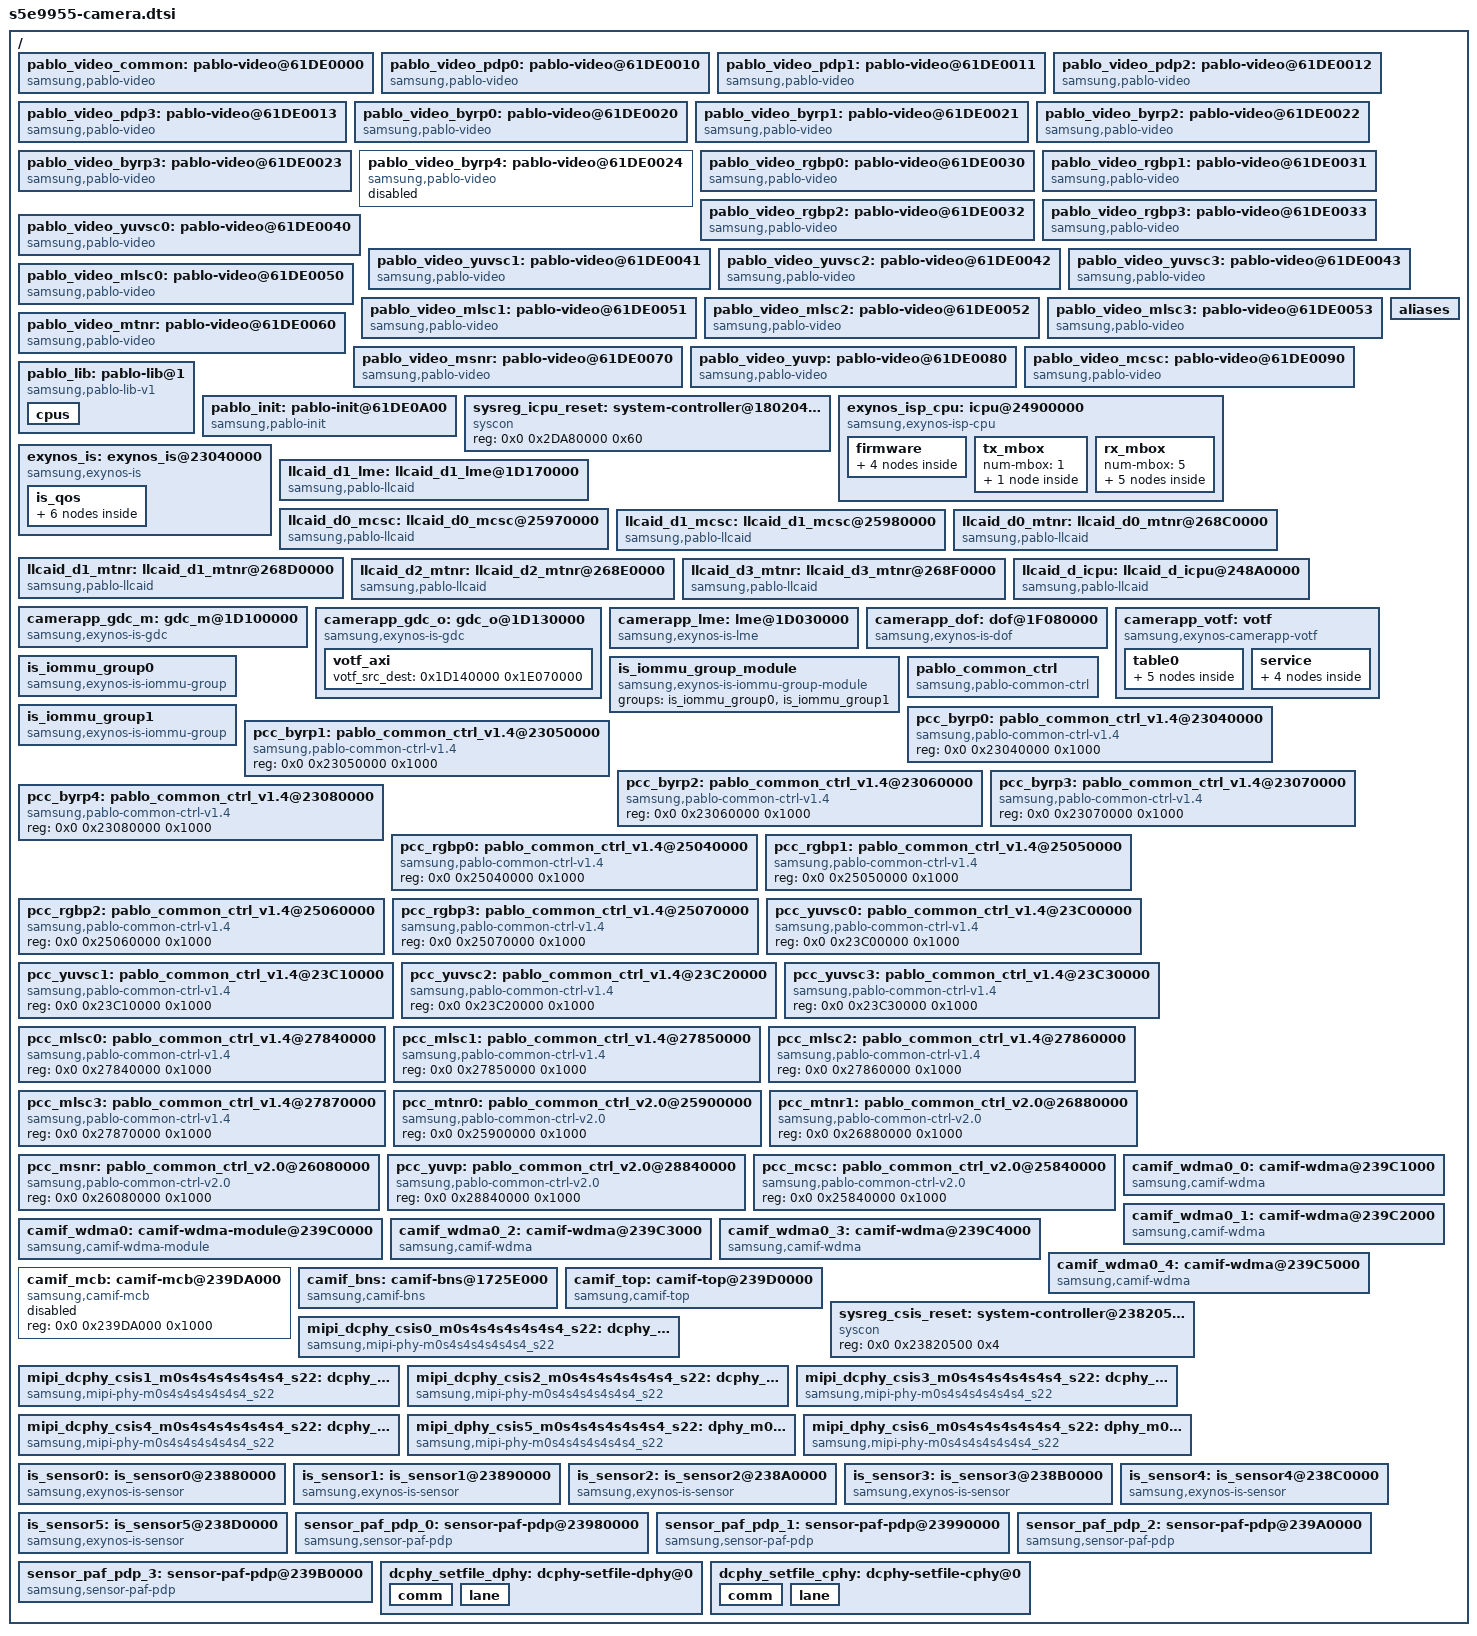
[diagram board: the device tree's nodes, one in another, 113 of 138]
// SPDX-License-Identifier: GPL-2.0
/*
 * SAMSUNG EXYNOS9955 SoC camera device tree source
 *
 * Copyright (c) 2024 Samsung Electronics Co., Ltd.
 *		http://www.samsung.com
 *
 * SAMSUNG EXYNOS9955 SoC camera device nodes are listed in this file.
 * EXYNOS9945 based board files can include this file and provide
 * values for board specific bindings.
 *
 * This program is free software; you can redistribute it and/or modify
 * it under the terms of the GNU General Public License version 2 as
 * published by the Free Software Foundation.
 */

#include <dt-bindings/clock/s5e9955.h>
#include <dt-bindings/interrupt-controller/arm-gic.h>
#include <dt-bindings/interrupt-controller/s5e9955.h>
#include <dt-bindings/camera/exynos_is_dt.h>
#include <dt-bindings/camera/votf.h>
#include "s5e9955-pinctrl.dtsi"

/ {
	pablo_video_common: pablo-video@61DE0000 {
		compatible = "samsung,pablo-video";
		device-type = <1>;	/* ISCHAIN */
		video-type = <0>;	/* LEADER */
		video-name = "COMMON";
		video-number = <0>;
		group-id = <36>;
		group-slot = <0>;

		pablo,v4l2-dev = <&exynos_is>;
	};

	pablo_video_pdp0: pablo-video@61DE0010 {
		compatible = "samsung,pablo-video";
		device-type = <1>;	/* ISCHAIN */
		video-type = <0>;	/* LEADER */
		video-name = "PDP0";
		video-number = <10>;
		group-id = <7>;
		group-slot = <1>;

		pablo,v4l2-dev = <&exynos_is>;
	};

	pablo_video_pdp1: pablo-video@61DE0011 {
		compatible = "samsung,pablo-video";
		device-type = <1>;	/* ISCHAIN */
		video-type = <0>;	/* LEADER */
		video-name = "PDP1";
		video-number = <11>;
		group-id = <8>;
		group-slot = <1>;

		pablo,v4l2-dev = <&exynos_is>;
	};

	pablo_video_pdp2: pablo-video@61DE0012 {
		compatible = "samsung,pablo-video";
		device-type = <1>;	/* ISCHAIN */
		video-type = <0>;	/* LEADER */
		video-name = "PDP2";
		video-number = <12>;
		group-id = <9>;
		group-slot = <1>;

		pablo,v4l2-dev = <&exynos_is>;
	};

	pablo_video_pdp3: pablo-video@61DE0013 {
		compatible = "samsung,pablo-video";
		device-type = <1>;	/* ISCHAIN */
		video-type = <0>;	/* LEADER */
		video-name = "PDP3";
		video-number = <13>;
		group-id = <10>;
		group-slot = <1>;

		pablo,v4l2-dev = <&exynos_is>;
	};

	pablo_video_byrp0: pablo-video@61DE0020 {
		compatible = "samsung,pablo-video";
		device-type = <1>;	/* ISCHAIN */
		video-type = <0>;	/* LEADER */
		video-name = "BYRP0";
		video-number = <20>;
		group-id = <15>;
		group-slot = <2>;

		pablo,v4l2-dev = <&exynos_is>;
	};

	pablo_video_byrp1: pablo-video@61DE0021 {
		compatible = "samsung,pablo-video";
		device-type = <1>;	/* ISCHAIN */
		video-type = <0>;	/* LEADER */
		video-name = "BYRP1";
		video-number = <21>;
		group-id = <16>;
		group-slot = <2>;

		pablo,v4l2-dev = <&exynos_is>;
	};

	pablo_video_byrp2: pablo-video@61DE0022 {
		compatible = "samsung,pablo-video";
		device-type = <1>;	/* ISCHAIN */
		video-type = <0>;	/* LEADER */
		video-name = "BYRP2";
		video-number = <22>;
		group-id = <17>;
		group-slot = <2>;

		pablo,v4l2-dev = <&exynos_is>;
	};

	pablo_video_byrp3: pablo-video@61DE0023 {
		compatible = "samsung,pablo-video";
		device-type = <1>;	/* ISCHAIN */
		video-type = <0>;	/* LEADER */
		video-name = "BYRP3";
		video-number = <23>;
		group-id = <18>;
		group-slot = <2>;

		pablo,v4l2-dev = <&exynos_is>;
	};

	pablo_video_byrp4: pablo-video@61DE0024 {
		compatible = "samsung,pablo-video";
		device-type = <1>;	/* ISCHAIN */
		video-type = <0>;	/* LEADER */
		video-name = "BYRP4";
		video-number = <24>;
		group-id = <19>;
		group-slot = <2>;

		pablo,v4l2-dev = <&exynos_is>;

		status = "disabled";
	};

	pablo_video_rgbp0: pablo-video@61DE0030 {
		compatible = "samsung,pablo-video";
		device-type = <1>;	/* ISCHAIN */
		video-type = <0>;	/* LEADER */
		video-name = "RGBP0";
		video-number = <30>;
		group-id = <20>;
		group-slot = <3>;

		pablo,v4l2-dev = <&exynos_is>;
	};

	pablo_video_rgbp1: pablo-video@61DE0031 {
		compatible = "samsung,pablo-video";
		device-type = <1>;	/* ISCHAIN */
		video-type = <0>;	/* LEADER */
		video-name = "RGBP1";
		video-number = <31>;
		group-id = <21>;
		group-slot = <3>;

		pablo,v4l2-dev = <&exynos_is>;
	};

	pablo_video_rgbp2: pablo-video@61DE0032 {
		compatible = "samsung,pablo-video";
		device-type = <1>;	/* ISCHAIN */
		video-type = <0>;	/* LEADER */
		video-name = "RGBP2";
		video-number = <32>;
		group-id = <22>;
		group-slot = <3>;

		pablo,v4l2-dev = <&exynos_is>;
	};

	pablo_video_rgbp3: pablo-video@61DE0033 {
		compatible = "samsung,pablo-video";
		device-type = <1>;	/* ISCHAIN */
		video-type = <0>;	/* LEADER */
		video-name = "RGBP3";
		video-number = <33>;
		group-id = <23>;
		group-slot = <3>;

		pablo,v4l2-dev = <&exynos_is>;
	};

	pablo_video_yuvsc0: pablo-video@61DE0040 {
		compatible = "samsung,pablo-video";
		device-type = <1>;	/* ISCHAIN */
		video-type = <0>;	/* LEADER */
		video-name = "YUVSC0";
		video-number = <40>;
		group-id = <24>;
		group-slot = <4>;

		pablo,v4l2-dev = <&exynos_is>;
	};

	pablo_video_yuvsc1: pablo-video@61DE0041 {
		compatible = "samsung,pablo-video";
		device-type = <1>;	/* ISCHAIN */
		video-type = <0>;	/* LEADER */
		video-name = "YUVSC1";
		video-number = <41>;
		group-id = <25>;
		group-slot = <4>;

		pablo,v4l2-dev = <&exynos_is>;
	};

	pablo_video_yuvsc2: pablo-video@61DE0042 {
		compatible = "samsung,pablo-video";
		device-type = <1>;	/* ISCHAIN */
		video-type = <0>;	/* LEADER */
		video-name = "YUVSC2";
		video-number = <42>;
		group-id = <26>;
		group-slot = <4>;

		pablo,v4l2-dev = <&exynos_is>;
	};

	pablo_video_yuvsc3: pablo-video@61DE0043 {
		compatible = "samsung,pablo-video";
		device-type = <1>;	/* ISCHAIN */
		video-type = <0>;	/* LEADER */
		video-name = "YUVSC3";
		video-number = <43>;
		group-id = <27>;
		group-slot = <4>;

		pablo,v4l2-dev = <&exynos_is>;
	};

	pablo_video_mlsc0: pablo-video@61DE0050 {
		compatible = "samsung,pablo-video";
		device-type = <1>;	/* ISCHAIN */
		video-type = <0>;	/* LEADER */
		video-name = "MLSC0";
		video-number = <50>;
		group-id = <28>;
		group-slot = <5>;

		pablo,v4l2-dev = <&exynos_is>;
	};

	pablo_video_mlsc1: pablo-video@61DE0051 {
		compatible = "samsung,pablo-video";
		device-type = <1>;	/* ISCHAIN */
		video-type = <0>;	/* LEADER */
		video-name = "MLSC1";
		video-number = <51>;
		group-id = <29>;
		group-slot = <5>;

		pablo,v4l2-dev = <&exynos_is>;
	};

	pablo_video_mlsc2: pablo-video@61DE0052 {
		compatible = "samsung,pablo-video";
		device-type = <1>;	/* ISCHAIN */
		video-type = <0>;	/* LEADER */
		video-name = "MLSC2";
		video-number = <52>;
		group-id = <30>;
		group-slot = <5>;

		pablo,v4l2-dev = <&exynos_is>;
	};

	pablo_video_mlsc3: pablo-video@61DE0053 {
		compatible = "samsung,pablo-video";
		device-type = <1>;	/* ISCHAIN */
		video-type = <0>;	/* LEADER */
		video-name = "MLSC3";
		video-number = <53>;
		group-id = <31>;
		group-slot = <5>;

		pablo,v4l2-dev = <&exynos_is>;
	};

	pablo_video_mtnr: pablo-video@61DE0060 {
		compatible = "samsung,pablo-video";
		device-type = <1>;	/* ISCHAIN */
		video-type = <0>;	/* LEADER */
		video-name = "MTNR";
		video-number = <60>;
		group-id = <32>;
		group-slot = <6>;

		pablo,v4l2-dev = <&exynos_is>;
	};

	pablo_video_msnr: pablo-video@61DE0070 {
		compatible = "samsung,pablo-video";
		device-type = <1>;	/* ISCHAIN */
		video-type = <0>;	/* LEADER */
		video-name = "MSNR";
		video-number = <70>;
		group-id = <33>;
		group-slot = <7>;

		pablo,v4l2-dev = <&exynos_is>;
	};

	pablo_video_yuvp: pablo-video@61DE0080 {
		compatible = "samsung,pablo-video";
		device-type = <1>;	/* ISCHAIN */
		video-type = <0>;	/* LEADER */
		video-name = "YUVP";
		video-number = <80>;
		group-id = <34>;
		group-slot = <8>;

		pablo,v4l2-dev = <&exynos_is>;
	};

	pablo_video_mcsc: pablo-video@61DE0090 {
		compatible = "samsung,pablo-video";
		device-type = <1>;	/* ISCHAIN */
		video-type = <0>;	/* LEADER */
		video-name = "MCSC";
		video-number = <90>;
		group-id = <35>;
		group-slot = <9>;

		pablo,v4l2-dev = <&exynos_is>;
		pablo,iommu-group = <&is_iommu_group0>;
	};

	pablo_lib: pablo-lib@1 {
		compatible = "samsung,pablo-lib-v1";
		status = "okay";

		cpus { /* 4:3:2:1 */
			cluster0 = <0>;		/* LIT */
			cluster1 = <4>;		/* MID_LF */
			cluster1h = <7>;	/* MID_HF */
			cluster2 = <9>;		/* BIG */
		};
	};

        pablo_init: pablo-init@61DE0A00 {
		compatible = "samsung,pablo-init";
		status = "okay";
	};

	sysreg_icpu_reset: system-controller@1802040c {
		compatible = "syscon";
		reg = <0x0 0x2DA80000 0x60>;
	};

	exynos_isp_cpu: icpu@24900000 {
		compatible = "samsung,exynos-isp-cpu";
		reg = <0x0 0x24900000 0x50>,
			<0x0 0x24910000 0x1000>,
			<0x0 0x24970000 0x2000>,
			<0x0 0x24980000 0x100>;
		reg-names = "mcuctl_core", "mcuctl", "sysctrl", "cstore";
		interrupts = <0 INTREQ__FROM_ICPU_TO_HOST_3 IRQ_TYPE_LEVEL_HIGH>, /* mbox0 */
				<0 INTREQ__FROM_ICPU_TO_HOST_4 IRQ_TYPE_LEVEL_HIGH>, /* mbox1 */
				<0 INTREQ__FROM_ICPU_TO_HOST_5 IRQ_TYPE_LEVEL_HIGH>, /* mbox2 */
				<0 INTREQ__FROM_ICPU_TO_HOST_6 IRQ_TYPE_LEVEL_HIGH>, /* mbox3 */
				<0 INTREQ__FROM_ICPU_TO_HOST_7 IRQ_TYPE_LEVEL_HIGH>; /* mbox4 */
		status = "okay";
		iommus = <&sysmmu_icpu_s0>;
		samsung,iommu-group = <&iommu_group_icpu>;
		samsung,reset-sysreg = <&sysreg_icpu_reset>;
		reset = <0 1>; /* reset bit, <core0 core1> */
		dma-coherent;
		samsung,iommu-reserved-map =
			<0x0 0x10000000 0x1000000>, /* FW binary */
			<0x0 0x00000000 0x10000000>, /* ICPU MMU */
			<0x0 0x24800000 0x200000>; /* ICPU SFR for using ICPU MMU 2M page*/
		memory-region = <&icpu_fw_rmem>;

		force-powerdown-seq =
			/* type addr mask val timeout */
			<0 0x24970024 0xFFFFFFFF 0x1      0>, /* Enable CA32 Transaction block */
			<0 0x24980030 0xFFFFFFFF 0x3      0>, /* DMA Flush */
			<1 0x24970028 0xFFFFFFFF 0x0   1000>, /* Wait until # of CA32  transaction is 0 */
			<1 0x24980034 0x24       0x24  1000>, /* Wait DMA  flush is done */

			<0 0x2497001C 0xFFFFFFFF 0x0      0>, /* Q-channel dependency disable */

			<0 0x24970004 0xFFFFFFFF 0x3F     0>, /* Q-channel disable(Always-on) */
			<0 0x24970030 0xFFFFFFFF 0x0      0>, /* Reset : Timers, WDT, GIC400, SYSCTRL */
			<0 0x2497002C 0xFFFFFFFF 0x0      0>, /* Reset : CA53, C_STORE */

			<0 0x2DA80040 0xFFFFFFFF 0x0     0>, /* PMU core reset : ICPU_CPU_OUT */
			<0 0x2DA8002C 0xFFFFFFFF 0x0     0>, /* PMU core reset : ICPU_CPU_OPTION */

			<0 0x24970004 0xFFFFFFFF 0x0     0>, /* Q-channel enable */
			<0 0x24970030 0xFFFFFFFF 0x3F    0>, /* Timers, WDT, GIC400, SYSCTRL */
			<0 0x2497002C 0xFFFFFFFF 0x3     0>, /* Core SW reset release */

			<0 0x24970050 0xFFFFFFFF 0x1     0>; /* Forced Power Down Enable */

		sw-reset-seq =
			<0 0x2DA80040 0xFFFFFFFF 0x0     0>, // ICPU_CPU_OUT in PMU_ICPU (PMU_SUB)
			<0 0x2DA8002C 0xFFFFFFFF 0x0     0>, // ICPU_CPU_OPTION in PMU_ICPU (PMU_SUB)

			// SW Reset Trigger for Peripherals
			<0 0x24970030 0xFFFFFFFF 0x0     0>, // Timers, WDT, GIC400, SYSCTRL
			<0 0x24970034 0xFFFFFFFF 0x0     0>, // MCUCTL_CORE/PERI

			<2 0x0        0xFFFFFFFF 0x0     1>, // delay 1us

			// SW Reset Release for Peripherals
			<0 0x24970030 0xFFFFFFFF 0x3F    0>, // Timers, WDT, GIC400, SYSCTRL
			<0 0x24970034 0xFFFFFFFF 0x3     0>, // MCUCTL_CORE/PERI

			<0 0x24970024 0xFFFFFFFF 0x0     0>, // Disable CA53 Transaction block
			<0 0x24970050 0xFFFFFFFF 0x0     0>, // Forced Power Down Disable
			<0 0x2497001C 0xFFFFFFFF 0x7     0>; // Q-channel dependency enable

		dbg-reg =
			/* start num */
			<0x0080 16>,
			<0x1490 40>;
		dbg-reg-name = "dbg", "mbox_dbg";

		num-cores = <2>; /* Dual core */

		samsung,imgloader-s2mpu-support;
		aarch64;
		firmware{
			binary{
				mem-id = <0>;
				cma-alloc;
				size = <0x1000000>;
				align = <0x200000>; /* 64K for S2MPU & ICPU MMU 2M page */
				signature-size = <0x210>; /* dec. 528 byte */
				signature-check;
				no-optimization;
			};

			heap{
				mem-id = <1>;
				dma-heap;
				heap-name = "system-uncached";
				size = <0x3700000>;
			};

			log{
				mem-id = <2>;
				dma-heap;
				heap-name = "system-uncached";
				size = <0x110000>;
			};

			/* mem-id = <3> is reserved for secure heap */

			dbg{
				mem-id = <4>;
				dma-heap;
				heap-name = "system-uncached";
				size = <0x100000>;
			};
		};

		tx_mbox{
			num-mbox = <1>;
			tx_mbox_0{
				int-enable-offset = <0x1004>;
				int-gen-offset = <0x1400>;
				int-status-offset = <0x100c>;
				max-data-len = <16>;
				data-offset = <0x1440>;
			};
		};

		rx_mbox{
			num-mbox = <5>;
			rx_mbox_0{
				int-gen-offset = <0x1200>;
				int-status-offset = <0x1008>;
				max-data-len = <8>;
				data-offset = <0x1240>;
			};
			rx_mbox_1{
				int-gen-offset = <0x1204>;
				int-status-offset = <0x1008>;
				max-data-len = <8>;
				data-offset = <0x1260>;
			};
			rx_mbox_2{
				int-gen-offset = <0x1208>;
				int-status-offset = <0x1008>;
				max-data-len = <8>;
				data-offset = <0x1280>;
			};
			rx_mbox_3{
				int-gen-offset = <0x120c>;
				int-status-offset = <0x1008>;
				max-data-len = <8>;
				data-offset = <0x12a0>;
			};
			rx_mbox_4{
				int-gen-offset = <0x1210>;
				int-status-offset = <0x1008>;
				max-data-len = <8>;
				data-offset = <0x12c0>;
			};
		};
	};

	exynos_is: exynos_is@23040000 {
		compatible = "samsung,exynos-is";
		reg = <0x0 0x23040000 0x6000>, /* BYRP0 */
			<0x0 0x23050000 0x6000>, /* BYRP1 */
			<0x0 0x23060000 0x6000>, /* BYRP2 */
			<0x0 0x23070000 0x6000>, /* BYRP3 */
			<0x0 0x23080000 0x6000>, /* BYRP4 */
			<0x0 0x25040000 0x7000>, /* RGBP0 */
			<0x0 0x25050000 0x7000>, /* RGBP1 */
			<0x0 0x25060000 0x7000>, /* RGBP2 */
			<0x0 0x25070000 0x7000>, /* RGBP3 */
			<0x0 0x23C00000 0x7000>, /* YUVSC0 */
			<0x0 0x23C10000 0x7000>, /* YUVSC1 */
			<0x0 0x23C20000 0x7000>, /* YUVSC2 */
			<0x0 0x23C30000 0x7000>, /* YUVSC3 */
			<0x0 0x27840000 0x7000>, /* MLSC0 */
			<0x0 0x27850000 0x7000>, /* MLSC1 */
			<0x0 0x27860000 0x7000>, /* MLSC2 */
			<0x0 0x27870000 0x7000>, /* MLSC3 */
			<0x0 0x25900000 0x8000>, /* MTNR0 */
			<0x0 0x26880000 0x8000>, /* MTNR1 */
			<0x0 0x26080000 0x6000>, /* MSNR */
			<0x0 0x28840000 0x7000>, /* YUVP */
			<0x0 0x25840000 0x8000>; /* MCSC */
		interrupts = <0 INTREQ__BYRP_C0_0 IRQ_TYPE_LEVEL_HIGH>, /* BYRP0_0 */
			<0 INTREQ__BYRP_C0_1 IRQ_TYPE_LEVEL_HIGH>, /* BYRP0_1 */
			<0 INTREQ__BYRP_C1_0 IRQ_TYPE_LEVEL_HIGH>, /* BYRP1_0 */
			<0 INTREQ__BYRP_C1_1 IRQ_TYPE_LEVEL_HIGH>, /* BYRP1_1 */
			<0 INTREQ__BYRP_C2_0 IRQ_TYPE_LEVEL_HIGH>, /* BYRP2_0 */
			<0 INTREQ__BYRP_C2_1 IRQ_TYPE_LEVEL_HIGH>, /* BYRP2_1 */
			<0 INTREQ__BYRP_C3_0 IRQ_TYPE_LEVEL_HIGH>, /* BYRP3_0 */
			<0 INTREQ__BYRP_C3_1 IRQ_TYPE_LEVEL_HIGH>, /* BYRP3_1 */
			<0 INTREQ__BYRP_C4_0 IRQ_TYPE_LEVEL_HIGH>, /* BYRP4_0 */
			<0 INTREQ__BYRP_C4_1 IRQ_TYPE_LEVEL_HIGH>, /* BYRP4_1 */
			<0 INTREQ__RGBP_C0_0 IRQ_TYPE_LEVEL_HIGH>, /* RGBP0_0 */
			<0 INTREQ__RGBP_C0_1 IRQ_TYPE_LEVEL_HIGH>, /* RGBP0_1 */
			<0 INTREQ__RGBP_C1_0 IRQ_TYPE_LEVEL_HIGH>, /* RGBP1_0 */
			<0 INTREQ__RGBP_C1_1 IRQ_TYPE_LEVEL_HIGH>, /* RGBP1_1 */
			<0 INTREQ__RGBP_C2_0 IRQ_TYPE_LEVEL_HIGH>, /* RGBP2_0 */
			<0 INTREQ__RGBP_C2_1 IRQ_TYPE_LEVEL_HIGH>, /* RGBP2_1 */
			<0 INTREQ__RGBP_C3_0 IRQ_TYPE_LEVEL_HIGH>, /* RGBP3_0 */
			<0 INTREQ__RGBP_C3_1 IRQ_TYPE_LEVEL_HIGH>, /* RGBP3_1 */
			<0 INTREQ__YUVSC_C0_0 IRQ_TYPE_LEVEL_HIGH>, /* YUVSC0_0 */
			<0 INTREQ__YUVSC_C0_1 IRQ_TYPE_LEVEL_HIGH>, /* YUVSC0_1 */
			<0 INTREQ__YUVSC_C1_0 IRQ_TYPE_LEVEL_HIGH>, /* YUVSC1_0 */
			<0 INTREQ__YUVSC_C1_1 IRQ_TYPE_LEVEL_HIGH>, /* YUVSC1_1 */
			<0 INTREQ__YUVSC_C2_0 IRQ_TYPE_LEVEL_HIGH>, /* YUVSC2_0 */
			<0 INTREQ__YUVSC_C2_1 IRQ_TYPE_LEVEL_HIGH>, /* YUVSC2_1 */
			<0 INTREQ__YUVSC_C3_0 IRQ_TYPE_LEVEL_HIGH>, /* YUVSC3_0 */
			<0 INTREQ__YUVSC_C3_1 IRQ_TYPE_LEVEL_HIGH>, /* YUVSC3_1 */
			<0 INTREQ__MLSC_C0_0 IRQ_TYPE_LEVEL_HIGH>, /* MLSC0_0 */
			<0 INTREQ__MLSC_C0_1 IRQ_TYPE_LEVEL_HIGH>, /* MLSC0_1 */
			<0 INTREQ__MLSC_C1_0 IRQ_TYPE_LEVEL_HIGH>, /* MLSC1_0 */
			<0 INTREQ__MLSC_C1_1 IRQ_TYPE_LEVEL_HIGH>, /* MLSC1_1 */
			<0 INTREQ__MLSC_C2_0 IRQ_TYPE_LEVEL_HIGH>, /* MLSC2_0 */
			<0 INTREQ__MLSC_C2_1 IRQ_TYPE_LEVEL_HIGH>, /* MLSC2_1 */
			<0 INTREQ__MLSC_C3_0 IRQ_TYPE_LEVEL_HIGH>, /* MLSC3_0 */
			<0 INTREQ__MLSC_C3_1 IRQ_TYPE_LEVEL_HIGH>, /* MLSC3_1 */
			<0 INTREQ__MTNR0_INTREQ_0__BLK_MCSC IRQ_TYPE_LEVEL_HIGH>, /* MTNR0_0 */
			<0 INTREQ__MTNR0_INTREQ_1__BLK_MCSC IRQ_TYPE_LEVEL_HIGH>, /* MTNR0_1 */
			<0 INTREQ__MTNR1_INTREQ_0__BLK_MTNR IRQ_TYPE_LEVEL_HIGH>, /* MTNR1_0 */
			<0 INTREQ__MTNR1_INTREQ_1__BLK_MTNR IRQ_TYPE_LEVEL_HIGH>, /* MTNR1_1 */
			<0 INTREQ__MSNR_0_INTREQ__BLK_MSNR IRQ_TYPE_LEVEL_HIGH>, /* MSNR_0 */
			<0 INTREQ__MSNR_1_INTREQ__BLK_MSNR IRQ_TYPE_LEVEL_HIGH>, /* MSNR_1 */
			<0 INTREQ__YUVP_0__BLK_YUVP IRQ_TYPE_LEVEL_HIGH>, /* YUVP_0 */
			<0 INTREQ__YUVP_1__BLK_YUVP IRQ_TYPE_LEVEL_HIGH>, /* YUVP_1 */
			<0 INTREQ__MCSC_INTREQ_0__BLK_MCSC IRQ_TYPE_LEVEL_HIGH>,    /* MCSC_0 */
			<0 INTREQ__MCSC_INTREQ_1__BLK_MCSC IRQ_TYPE_LEVEL_HIGH>;    /* MCSC_1 */
		pinctrl-names = "default","release";
		pinctrl-0 = <>;
		pinctrl-1 = <>;

		clocks =
		       /* Sensor MCLKs */
		       <&clock DOUT_DIV_CLKCMU_CIS_CLK0>,
		       <&clock DOUT_DIV_CLKCMU_CIS_CLK1>,
		       <&clock DOUT_DIV_CLKCMU_CIS_CLK2>,
		       <&clock DOUT_DIV_CLKCMU_CIS_CLK3>,
		       <&clock DOUT_DIV_CLKCMU_CIS_CLK4>,
		       <&clock DOUT_DIV_CLKCMU_CIS_CLK5>,
		       <&clock DOUT_DIV_CLKCMU_CIS_CLK6>,

		       <&clock GATE_DFTMUX_CMU_QCH_CIS_CLK0>,
		       <&clock GATE_DFTMUX_CMU_QCH_CIS_CLK1>,
		       <&clock GATE_DFTMUX_CMU_QCH_CIS_CLK2>,
		       <&clock GATE_DFTMUX_CMU_QCH_CIS_CLK3>,
		       <&clock GATE_DFTMUX_CMU_QCH_CIS_CLK4>,
		       <&clock GATE_DFTMUX_CMU_QCH_CIS_CLK5>,
		       <&clock GATE_DFTMUX_CMU_QCH_CIS_CLK6>,

		       /* MIPI-PHYs & CSIS Links */
		       <&clock GATE_MIPI_PHY_LINK_WRAP_QCH_CSIS0>,
		       <&clock GATE_MIPI_PHY_LINK_WRAP_QCH_CSIS1>,
		       <&clock GATE_MIPI_PHY_LINK_WRAP_QCH_CSIS2>,
		       <&clock GATE_MIPI_PHY_LINK_WRAP_QCH_CSIS3>,
		       <&clock GATE_MIPI_PHY_LINK_WRAP_QCH_CSIS4>,
		       <&clock GATE_MIPI_PHY_LINK_WRAP_QCH_CSIS5>,
		       <&clock GATE_MIPI_PHY_LINK_WRAP_QCH_CSIS6>,

			/* CSIS WDMA */
		       <&clock GATE_CSIS_PDP_QCH_DMA>,

		       /* PDP */
		       <&clock GATE_CSIS_PDP_QCH_PDP>,

		       /* ISCHAIN */
		       <&clock GATE_SIPU_BYRP_QCH>,
		       <&clock GATE_RGBP_QCH>,
		       <&clock GATE_MLSC_QCH>,
		       <&clock GATE_MTNR_QCH>,
		       <&clock GATE_MSNR_QCH>,
		       <&clock GATE_YUVP_QCH>,
		       <&clock GATE_MCSC_QCH>;
		clock-names =
			/* Sensor MCLKs */
			"DOUT_DIV_CLKCMU_CIS_CLK0",
			"DOUT_DIV_CLKCMU_CIS_CLK1",
			"DOUT_DIV_CLKCMU_CIS_CLK2",
			"DOUT_DIV_CLKCMU_CIS_CLK3",
			"DOUT_DIV_CLKCMU_CIS_CLK4",
			"DOUT_DIV_CLKCMU_CIS_CLK5",
			"DOUT_DIV_CLKCMU_CIS_CLK6",

			"GATE_DFTMUX_CMU_QCH_CIS_CLK0",
			"GATE_DFTMUX_CMU_QCH_CIS_CLK1",
			"GATE_DFTMUX_CMU_QCH_CIS_CLK2",
			"GATE_DFTMUX_CMU_QCH_CIS_CLK3",
			"GATE_DFTMUX_CMU_QCH_CIS_CLK4",
			"GATE_DFTMUX_CMU_QCH_CIS_CLK5",
			"GATE_DFTMUX_CMU_QCH_CIS_CLK6",

			/* MIPI-PHYs & CSIS Links */
			"GATE_MIPI_PHY_LINK_WRAP_QCH_CSIS0",
			"GATE_MIPI_PHY_LINK_WRAP_QCH_CSIS1",
			"GATE_MIPI_PHY_LINK_WRAP_QCH_CSIS2",
			"GATE_MIPI_PHY_LINK_WRAP_QCH_CSIS3",
			"GATE_MIPI_PHY_LINK_WRAP_QCH_CSIS4",
			"GATE_MIPI_PHY_LINK_WRAP_QCH_CSIS5",
			"GATE_MIPI_PHY_LINK_WRAP_QCH_CSIS6",

			/* CSIS WDMA */
			"GATE_CSIS_PDP_QCH_DMA",

			/* PDP */
			"GATE_CSIS_PDP_QCH_PDP",

			/* ISCHAIN */
			"GATE_SIPU_BYRP_QCH",
			"GATE_RGBP_QCH",
			"GATE_MLSC_QCH",
			"GATE_MTNR_QCH",
			"GATE_MSNR_QCH",
			"GATE_YUVP_QCH",
			"GATE_MCSC_QCH";

		iommus =
		       <&sysmmu_csis_s0>,
		       <&sysmmu_brp_s0>,
		       <&sysmmu_rgbp_s0>,
		       <&sysmmu_mlsc_s0>,
		       <&sysmmu_mtnr_s0>,
		       <&sysmmu_yuvp_s0>,
		       <&sysmmu_mcsc_s0>;
		samsung,iommu-group = <&iommu_group_is>;

		itmon_port_name =
				"ICPU",
				"CSIS",
				"CSTAT",
				"BRP",
				"RGBP",
				"DLNE",
				"MCFP",
				"YUVP",
				"DLFE",
				"MCSC";

		status = "ok";
		#cooling-cells = <2>; /* min followed by max */
		/* ewf-index = <EWF_CMU_BUSC>; */
		list-scen-bts = "camera_default", "camera_heavy";
		num_of_3aa = <0>;
		num_of_lme = <0>;
		num_of_isp = <0>;
		num_of_byrp = <4>;
		num_of_rgbp = <4>;
		num_of_mcsc = <1>;
		num_of_vra = <0>;
		num_of_clh = <0>;
		num_of_ypp = <1>;
		num_of_shrp = <0>;
		num_of_mcfp = <0>;
		num_of_dlfe = <0>;
		num_of_yuvsc = <4>;
		num_of_mlsc = <4>;
		num_of_mtnr0 = <1>;
		num_of_mtnr1 = <1>;
		num_of_msnr = <1>;

		is_qos {
			CSIS { /* CSIS, PDP */
				typ = <IS_DVFS_CSIS>;
				lev = <0      1      2      3      4      5      6      7      8>;
				frq = <745    664    533    467    400    332    267    234    166>;
				qos = <745000 664000 533000 467000 400000 332000 267000 234000 166000>;
				path = <IS_DVFS_PATH_OTF>;
			};

			CAM { /* BYRP, RGBP, YUVSC, MLSC */
				typ = <IS_DVFS_CAM>;
				lev = <0      1      2      3      4      5      6      7      8>;
				frq = <745    664    533    467    400    332    267    234    166>;
				qos = <745000 664000 533000 467000 400000 332000 267000 234000 166000>;
				path = <IS_DVFS_PATH_OTF IS_DVFS_PATH_M2M>;
			};

			ISP { /* DLFE, MTNR, MSNR, YUVP, MCSC */
				typ = <IS_DVFS_ISP>;
				lev = <0      1      2      3      4      5      6      7      8      9>;
				frq = <745    664    533    467    400    373    332    267    234    166>;
				qos = <745000 664000 533000 467000 400000 373000 332000 267000 234000 166000>;
				path = <IS_DVFS_PATH_M2M>;
			};

			INT_CAM { /* LME, GDC_O, GDC_M, DOF */
				typ = <IS_DVFS_INT_CAM>;
				lev = <0      1      2      3      4      5      6      7>;
				frq = <745    533    467    400    332    267    234    166>;
				qos = <745000 533000 467000 400000 332000 267000 234000 166000>;
				path = <IS_DVFS_PATH_M2M>;
			};

			ICPU { /* ICPU */
				typ = <IS_DVFS_ICPU>;
				lev = <0       1       2       3      4      5      6      7      8      9>;
				frq = <1500    1200    1066    934    800    664    533    332    267    200>;
				qos = <1500000 1200000 1066000 934000 800000 664000 533000 332000 267000 200000>;
				path = <IS_DVFS_PATH_M2M>;
			};

			MIF {
				typ = <IS_DVFS_MIF>;
				lev = <0       1       2       3       4       5       6       7       8      9     10     11>;
				frq = <4800    4205    3172    2730    2288    2028    1539    1352    1014    845    676    421>;
				qos = <4800000 4205000 3172000 2730000 2288000 2028000 1539000 1352000 1014000 845000 676000 421000>;
				path = <IS_DVFS_PATH_M2M>;
			};
		};
	};

	llcaid_d1_lme: llcaid_d1_lme@1D170000 {
		compatible = "samsung,pablo-llcaid";
		reg = <0x0 0x1D170420 0xC>,
			<0x0 0x1D170440 0xC>;
		/* enable_val ctlr_val*/
		#val-cells = <2>;
		stream = <0x301 0x1000201>,
			<0x20301 0x1000201>;
	};

	llcaid_d0_mcsc: llcaid_d0_mcsc@25970000 {
		compatible = "samsung,pablo-llcaid";
		reg = <0x0 0x25972020 0xC>,
			<0x0 0x25972420 0xC>;
		#val-cells = <2>;
		stream = <0x101 0xB000000>,
			<0x101 0xB000000>;
	};

	llcaid_d1_mcsc: llcaid_d1_mcsc@25980000 {
		compatible = "samsung,pablo-llcaid";
		reg = <0x0 0x25981420 0xC>;
		#val-cells = <2>;
		stream = <0x101 0xB000000>;
	};

	llcaid_d0_mtnr: llcaid_d0_mtnr@268C0000 {
		compatible = "samsung,pablo-llcaid";
		reg = <0x0 0x268C1820 0xC>;
		#val-cells = <2>;
		stream = <0x101 0xB000000>;
	};

	llcaid_d1_mtnr: llcaid_d1_mtnr@268D0000 {
		compatible = "samsung,pablo-llcaid";
		reg = <0x0 0x268D0420 0xC>,
			<0x0 0x268D0820 0xC>;
		#val-cells = <2>;
		stream = <0x101 0xB000000>,
			<0x101 0xB000000>;
	};

	llcaid_d2_mtnr: llcaid_d2_mtnr@268E0000 {
		compatible = "samsung,pablo-llcaid";
		reg = <0x0 0x268E0420 0xC>,
			<0x0 0x268E0820 0xC>,
			<0x0 0x268E0C20 0xC>,
			<0x0 0x268E1020 0xC>;
		#val-cells = <2>;
		stream = <0x101 0xB000000>,
			<0x101 0xB000000>,
			<0x101 0xB000000>,
			<0x101 0xB000000>;
	};

	llcaid_d3_mtnr: llcaid_d3_mtnr@268F0000 {
		compatible = "samsung,pablo-llcaid";
		reg = <0x0 0x268F0820 0xC>,
			<0x0 0x268F0C20 0xC>,
			<0x0 0x268F1020 0xC>;
		#val-cells = <2>;
		stream = <0x101 0xB000000>,
			<0x101 0xB000000>,
			<0x101 0xB000000>;
	};

	llcaid_d_icpu: llcaid_d_icpu@248A0000 {
		compatible = "samsung,pablo-llcaid";
		reg = <0x0 0x248A0820 0xC>,
			<0x0 0x248A0840 0xC>;
		#val-cells = <2>;
		stream = <0x101 0xD000000>,
			<0x10101 0xD000000>;
	};

	aliases {
		llcaid0 = &llcaid_d1_lme;
		llcaid1 = &llcaid_d0_mcsc;
		llcaid2	= &llcaid_d1_mcsc;
		llcaid3	= &llcaid_d0_mtnr;
		llcaid4	= &llcaid_d1_mtnr;
		llcaid5	= &llcaid_d2_mtnr;
		llcaid6	= &llcaid_d3_mtnr;
		llcaid7	= &llcaid_d_icpu;
	};

	camerapp_gdc_m: gdc_m@1D100000 {
		compatible = "samsung,exynos-is-gdc";
		reg = <0x0 0x1D100000 0x10000>; /* GDC */
		interrupts = <0 INTREQ__GDC_M_IRQ_0__BLK_LME IRQ_TYPE_LEVEL_HIGH>, /* GDC_0 */
			<0 INTREQ__GDC_M_IRQ_1__BLK_LME IRQ_TYPE_LEVEL_HIGH>;    /* GDC_1 */
		interrupt-names = "GDCM_0", "GDCM_1";
		pinctrl-names = "default","release";
		pinctrl-0 = <>;
		pinctrl-1 = <>;

		status = "okay";
		iommus = <&sysmmu_lme_s0>;
		samsung,iommu-group = <&iommu_group_is>;
		#cooling-cells = <2>; /* min followed by max */
		dma-coherent;
	};

	camerapp_gdc_o: gdc_o@1D130000 {
		compatible = "samsung,exynos-is-gdc";
		reg = <0x0 0x1D130000 0x10000>; /* GDC */
		interrupts = <0 INTREQ__GDC_O_IRQ_0__BLK_LME IRQ_TYPE_LEVEL_HIGH>, /* GDC_0 */
			<0 INTREQ__GDC_O_IRQ_1__BLK_LME IRQ_TYPE_LEVEL_HIGH>;    /* GDC_1 */
		interrupt-names = "GDCO_0", "GDCO_1";
		pinctrl-names = "default","release";
		pinctrl-0 = <>;
		pinctrl-1 = <>;

		status = "okay";
		iommus = <&sysmmu_lme_s0>;
		samsung,iommu-group = <&iommu_group_is>;
		samsung,iommu-identity-map = <0x0 0x1E070000 0x10000>;
		#cooling-cells = <2>; /* min followed by max */
		dma-coherent;

		hdr10p;  /* gdc_o has HDR10p hw stat module */

		votf_axi {
			votf_src_dest = <0x1D140000 0x1E070000>;
		};
	};

	aliases {
		pablo-gdc0 = &camerapp_gdc_o;
		pablo-gdc1 = &camerapp_gdc_m;
	};

	camerapp_lme: lme@1D030000 {
		compatible = "samsung,exynos-is-lme";
		reg = <0x0 0x1D030000 0x10000>; /* LME */
		interrupts = <0 INTREQ__LME_O_INT0__BLK_LME IRQ_TYPE_LEVEL_HIGH>; /* LME_0 */
		pinctrl-names = "default","release";
		pinctrl-0 = <>;
		pinctrl-1 = <>;

		status = "okay";
		iommus = <&sysmmu_lme_s0>;
		samsung,iommu-group = <&iommu_group_is>;
		#cooling-cells = <2>; /* min followed by max */
		#dma-coherent;
		iommu_group_for_cloader = <1>; /* cloader is not support io coherency */
	};

	camerapp_dof: dof@1F080000 {
		compatible = "samsung,exynos-is-dof";
		reg = <0x0 0x1F080000 0x10000>; /* DOF */
		interrupts = <0 INTREQ__DOF_INT_0__BLK_DOF IRQ_TYPE_LEVEL_HIGH>, /* DOF_0 */
			<0 INTREQ__DOF_INT_1__BLK_DOF IRQ_TYPE_LEVEL_HIGH>; /* DOF_1 */
		pinctrl-names = "default","release";
		pinctrl-0 = <>;
		pinctrl-1 = <>;

		status = "okay";
		iommus = <&sysmmu_dof_s0>;
		samsung,iommu-group = <&iommu_group_is>;
		#cooling-cells = <2>; /* min followed by max */
		#dma-coherent;
		iommu_group_for_cloader = <1>; /* cloader is not support io coherency */
	};

	camerapp_votf: votf {
		compatible = "samsung,exynos-camerapp-votf";
		iommus = <&sysmmu_csis_s0>,
			<&sysmmu_brp_s0>,
			<&sysmmu_rgbp_s0>,
			<&sysmmu_mlsc_s0>,
			<&sysmmu_mtnr_s0>,
			<&sysmmu_yuvp_s0>,
			<&sysmmu_mcsc_s0>;
		samsung,iommu-group = <&iommu_group_is>;
		samsung,iommu-identity-map =	<0x0 0x27900000 0x10000>,
						<0x0 0x25860000 0x10000>,
						<0x0 0x1D150000 0x10000>,
						<0x0 0x1D140000 0x10000>;
		status = "okay";
		use_axi;

		table0{
			/* use, base address, ip num, id cnt, C2SERV/C2AGENT, TWS/TRS, module type */
			mlsc_rdma	{ info = <1 0x27900000 0x2790 2 C2SERV TRS M16S16>; };
			mcsc_wdma	{ info = <1 0x25860000 0x2586 15 C2SERV TWS M16S16>; };
			gdco_rdma	{ info = <1 0x1D150000 0x1D15 2 C2SERV TRS M16S16>; };
			gdco_wdma	{ info = <1 0x1D140000 0x1D14 2 C2SERV TWS M16S16>; };
			mfc_rdma	{ info = <0 0x1E070000 0x1E07 2 C2SERV TRS M16S16>; };
		};

		service {
			/* num, tws addr, trs addr, tws gap, trs gap */
			m0s4 { info = <0 0x0 0x100 0x1C 0x2C>; };
			m2s2 { info = <1 0x100 0x200 0x1C 0x2C>; };
			m3s1 { info = <2 0x100 0x200 0x1C 0x2C>; };
			m16s16 { info = <3 0x100 0x300 0x1C 0x2C>; };
		};
	};

	is_iommu_group_module: is_iommu_group_module {
		compatible = "samsung,exynos-is-iommu-group-module";
		groups = <&is_iommu_group0>, <&is_iommu_group1>;
	};

	aliases {
		iommu-group-module0 = &is_iommu_group_module;
	};

	is_iommu_group0: is_iommu_group0 {
		compatible = "samsung,exynos-is-iommu-group";
		iommus = <&sysmmu_mcsc_s0>;
		samsung,iommu-group = <&iommu_group_is>;
		dma-coherent;
	};

	/* for gdc cloader without dma-coherent */
	is_iommu_group1: is_iommu_group1 {
		compatible = "samsung,exynos-is-iommu-group";
		iommus = <&sysmmu_lme_s0>;
		samsung,iommu-group = <&iommu_group_is>;
	};

	aliases {
		iommu-group0 = &is_iommu_group0;
		iommu-group1 = &is_iommu_group1;
	};

	pablo_common_ctrl: pablo_common_ctrl {
		compatible = "samsung,pablo-common-ctrl";
		pccs = <&pcc_byrp0>, <&pcc_byrp1>, <&pcc_byrp2>, <&pcc_byrp3>, <&pcc_byrp4>,
		<&pcc_rgbp0>, <&pcc_rgbp1>, <&pcc_rgbp2>, <&pcc_rgbp3>,
		<&pcc_yuvsc0>, <&pcc_yuvsc1>, <&pcc_yuvsc2>, <&pcc_yuvsc3>,
		<&pcc_mlsc0>, <&pcc_mlsc1>, <&pcc_mlsc2>, <&pcc_mlsc3>,
		<&pcc_mtnr0>, <&pcc_mtnr1>, <&pcc_msnr>, <&pcc_yuvp>, <&pcc_mcsc>;
	};

	pcc_byrp0: pablo_common_ctrl_v1.4@23040000 {
		compatible = "samsung,pablo-common-ctrl-v1.4";
		reg = <0x0 0x23040000 0x1000>;
	};

	pcc_byrp1: pablo_common_ctrl_v1.4@23050000 {
		compatible = "samsung,pablo-common-ctrl-v1.4";
		reg = <0x0 0x23050000 0x1000>;
	};

	pcc_byrp2: pablo_common_ctrl_v1.4@23060000 {
		compatible = "samsung,pablo-common-ctrl-v1.4";
		reg = <0x0 0x23060000 0x1000>;
	};

	pcc_byrp3: pablo_common_ctrl_v1.4@23070000 {
		compatible = "samsung,pablo-common-ctrl-v1.4";
		reg = <0x0 0x23070000 0x1000>;
	};

	pcc_byrp4: pablo_common_ctrl_v1.4@23080000 {
		compatible = "samsung,pablo-common-ctrl-v1.4";
		reg = <0x0 0x23080000 0x1000>;
	};

	pcc_rgbp0: pablo_common_ctrl_v1.4@25040000 {
		compatible = "samsung,pablo-common-ctrl-v1.4";
		reg = <0x0 0x25040000 0x1000>;
	};

	pcc_rgbp1: pablo_common_ctrl_v1.4@25050000 {
		compatible = "samsung,pablo-common-ctrl-v1.4";
		reg = <0x0 0x25050000 0x1000>;
	};

	pcc_rgbp2: pablo_common_ctrl_v1.4@25060000 {
		compatible = "samsung,pablo-common-ctrl-v1.4";
		reg = <0x0 0x25060000 0x1000>;
	};

	pcc_rgbp3: pablo_common_ctrl_v1.4@25070000 {
		compatible = "samsung,pablo-common-ctrl-v1.4";
		reg = <0x0 0x25070000 0x1000>;
	};

	pcc_yuvsc0: pablo_common_ctrl_v1.4@23C00000 {
		compatible = "samsung,pablo-common-ctrl-v1.4";
		reg = <0x0 0x23C00000 0x1000>;
	};

	pcc_yuvsc1: pablo_common_ctrl_v1.4@23C10000 {
		compatible = "samsung,pablo-common-ctrl-v1.4";
		reg = <0x0 0x23C10000 0x1000>;
	};

	pcc_yuvsc2: pablo_common_ctrl_v1.4@23C20000 {
		compatible = "samsung,pablo-common-ctrl-v1.4";
		reg = <0x0 0x23C20000 0x1000>;
	};

	pcc_yuvsc3: pablo_common_ctrl_v1.4@23C30000 {
		compatible = "samsung,pablo-common-ctrl-v1.4";
		reg = <0x0 0x23C30000 0x1000>;
	};

	pcc_mlsc0: pablo_common_ctrl_v1.4@27840000 {
		compatible = "samsung,pablo-common-ctrl-v1.4";
		reg = <0x0 0x27840000 0x1000>;
	};

	pcc_mlsc1: pablo_common_ctrl_v1.4@27850000 {
		compatible = "samsung,pablo-common-ctrl-v1.4";
		reg = <0x0 0x27850000 0x1000>;
	};

	pcc_mlsc2: pablo_common_ctrl_v1.4@27860000 {
		compatible = "samsung,pablo-common-ctrl-v1.4";
		reg = <0x0 0x27860000 0x1000>;
	};

	pcc_mlsc3: pablo_common_ctrl_v1.4@27870000 {
		compatible = "samsung,pablo-common-ctrl-v1.4";
		reg = <0x0 0x27870000 0x1000>;
	};

	pcc_mtnr0: pablo_common_ctrl_v2.0@25900000 {
		compatible = "samsung,pablo-common-ctrl-v2.0";
		reg = <0x0 0x25900000 0x1000>;
	};

	pcc_mtnr1: pablo_common_ctrl_v2.0@26880000 {
		compatible = "samsung,pablo-common-ctrl-v2.0";
		reg = <0x0 0x26880000 0x1000>;
	};

	pcc_msnr: pablo_common_ctrl_v2.0@26080000 {
		compatible = "samsung,pablo-common-ctrl-v2.0";
		reg = <0x0 0x26080000 0x1000>;
	};

	pcc_yuvp: pablo_common_ctrl_v2.0@28840000 {
		compatible = "samsung,pablo-common-ctrl-v2.0";
		reg = <0x0 0x28840000 0x1000>;
	};

	pcc_mcsc: pablo_common_ctrl_v2.0@25840000 {
		compatible = "samsung,pablo-common-ctrl-v2.0";
		reg = <0x0 0x25840000 0x1000>;
	};

	camif_wdma0: camif-wdma-module@239C0000 {
		compatible = "samsung,camif-wdma-module";
		reg = <0x0 0x239C0000 0x300>;
		reg-names = "ctl";
		channels = <&camif_wdma0_0>,
			<&camif_wdma0_1>,
			<&camif_wdma0_2>,
			<&camif_wdma0_3>,
			<&camif_wdma0_4>;
	};

	aliases {
		wdma-module0 = &camif_wdma0;
	};

	camif_wdma0_0: camif-wdma@239C1000 {
		compatible = "samsung,camif-wdma";
		reg = <0x0 0x239D0240 0x4>,	/* input MUX */
			<0x0 0x239C1400 0x100>,	/* CTL */
			<0x0 0x239C1000 0x100>,	/* VC0 */
			<0x0 0x239C1100 0x100>,	/* VC1 */
			<0x0 0x239C1200 0x100>,	/* VC2 */
			<0x0 0x239C1300 0x100>;	/* VC3 */
		reg-names = "mux", "ctl", "vc0", "vc1", "vc2", "vc3";
		interrupts = <GIC_SPI INTREQ__CSIS_DMA0 IRQ_TYPE_LEVEL_HIGH>;
		interrupt-names = "dma";
		module = <&camif_wdma0>;
	};

	camif_wdma0_1: camif-wdma@239C2000 {
		compatible = "samsung,camif-wdma";
		reg = <0x0 0x239D0244 0x4>,	/* input MUX */
			<0x0 0x239C2400 0x100>,	/* CTL */
			<0x0 0x239C2000 0x100>,	/* VC0 */
			<0x0 0x239C2100 0x100>,	/* VC1 */
			<0x0 0x239C2200 0x100>,	/* VC2 */
			<0x0 0x239C2300 0x100>;	/* VC3 */
		reg-names = "mux", "ctl", "vc0", "vc1", "vc2", "vc3";
		interrupts = <GIC_SPI INTREQ__CSIS_DMA1 IRQ_TYPE_LEVEL_HIGH>;
		interrupt-names = "dma";
		module = <&camif_wdma0>;
	};

	camif_wdma0_2: camif-wdma@239C3000 {
		compatible = "samsung,camif-wdma";
		reg = <0x0 0x239D0248 0x4>,	/* input MUX */
			<0x0 0x239C3400 0x100>,	/* CTL */
			<0x0 0x239C3000 0x100>,	/* VC0 */
			<0x0 0x239C3100 0x100>,	/* VC1 */
			<0x0 0x239C3200 0x100>,	/* VC2 */
			<0x0 0x239C3300 0x100>;	/* VC3 */
		reg-names = "mux", "ctl", "vc0", "vc1", "vc2", "vc3";
		interrupts = <GIC_SPI INTREQ__CSIS_DMA2 IRQ_TYPE_LEVEL_HIGH>;
		interrupt-names = "dma";
		module = <&camif_wdma0>;
	};

	camif_wdma0_3: camif-wdma@239C4000 {
		compatible = "samsung,camif-wdma";
		reg = <0x0 0x239D024C 0x4>,	/* input MUX */
			<0x0 0x239C4400 0x100>,	/* CTL */
			<0x0 0x239C4000 0x100>,	/* VC0 */
			<0x0 0x239C4100 0x100>,	/* VC1 */
			<0x0 0x239C4200 0x100>,	/* VC2 */
			<0x0 0x239C4300 0x100>;	/* VC3 */
		reg-names = "mux", "ctl", "vc0", "vc1", "vc2", "vc3";
		interrupts = <GIC_SPI INTREQ__CSIS_DMA3 IRQ_TYPE_LEVEL_HIGH>;
		interrupt-names = "dma";
		module = <&camif_wdma0>;
	};

	camif_wdma0_4: camif-wdma@239C5000 {
		compatible = "samsung,camif-wdma";
		reg = <0x0 0x239D0250 0x4>,	/* input MUX */
			<0x0 0x239C5400 0x100>,	/* CTL */
			<0x0 0x239C5000 0x100>,	/* VC0 */
			<0x0 0x239C5100 0x100>,	/* VC1 */
			<0x0 0x239C5200 0x100>,	/* VC2 */
			<0x0 0x239C3000 0x100>;	/* VC3 */
		reg-names = "mux", "ctl", "vc0", "vc1", "vc2", "vc3";
		interrupts = <GIC_SPI INTREQ__CSIS_DMA4 IRQ_TYPE_LEVEL_HIGH>;
		interrupt-names = "dma";
		module = <&camif_wdma0>;
	};

	aliases {
		wdma0 = &camif_wdma0_0;
		wdma1 = &camif_wdma0_1;
		wdma2 = &camif_wdma0_2;
		wdma3 = &camif_wdma0_3;
		wdma4 = &camif_wdma0_4;
	};

	camif_mcb: camif-mcb@239DA000 {
		compatible = "samsung,camif-mcb";
		reg = <0x0 0x239DA000 0x1000>;
		status = "disabled";
	};

	camif_bns: camif-bns@1725E000 {
		compatible = "samsung,camif-bns";
		reg = <0x0 0x239DE000 0x100>,
		    <0x0 0x239D020C 0x4>; /* CSIS_PDP_BNS_MUX */
		reg-names = "ctl", "mux";

		mux = <0 1 2 3>; /* BNS in/out channel selection */
		dma_mux = <0x24>; /* DMA mux for BNS out */
		status = "okay";
	};

	camif_top: camif-top@239D0000 {
		compatible = "samsung,camif-top";
		reg = <0x0 0x239D0000 0x10000>;
		interrupts = <0 INTREQ__MPC IRQ_TYPE_LEVEL_HIGH>,
				<0 INTREQ__NFI IRQ_TYPE_LEVEL_HIGH>;
	};

	sysreg_csis_reset: system-controller@23820500 {
		compatible = "syscon";
		reg = <0x0 0x23820500 0x4>;
	};

	mipi_dcphy_csis0_m0s4s4s4s4s4s4_s22: dcphy_m0s4s4s4s4s4s4_s22_csi0@238F1300 {
		/* DPHY 6.5 Gbps 4lane */
		/* CPHY 6.5 Gbps 3lane */
		compatible = "samsung,mipi-phy-m0s4s4s4s4s4s4_s22";
		samsung,pmu-syscon = <&pmu_system_controller>;
		power-gating = <0x648>; /* PMU address offset */
		samsung,reset-sysreg = <&sysreg_csis_reset>;
		reset = <0>; /* reset bit */
		reg = <0x0 0x238F1300 0x500>;
		owner = <1>; /* 0: DSI,  1: CSI */
		#phy-cells = <0>;
	};

	mipi_dcphy_csis1_m0s4s4s4s4s4s4_s22: dcphy_m0s4s4s4s4s4s4_s22_csi1@238F1B00 {
		/* DPHY 6.5 Gbps 4lane */
		/* CPHY 6.5 Gbps 3lane */
		compatible = "samsung,mipi-phy-m0s4s4s4s4s4s4_s22";
		samsung,pmu-syscon = <&pmu_system_controller>;
		power-gating = <0x64C>; /* PMU address offset */
		samsung,reset-sysreg = <&sysreg_csis_reset>;
		reset = <1>; /* reset bit */
		reg = <0x0 0x238F1B00 0x500>;
		owner = <1>; /* 0: DSI,  1: CSI */
		#phy-cells = <0>;
	};

	mipi_dcphy_csis2_m0s4s4s4s4s4s4_s22: dcphy_m0s4s4s4s4s4s4_s22_csi2@238F2300 {
		/* DPHY 6.5 Gbps 4lane */
		/* CPHY 6.5 Gbps 3lane */
		compatible = "samsung,mipi-phy-m0s4s4s4s4s4s4_s22";
		samsung,pmu-syscon = <&pmu_system_controller>;
		power-gating = <0x650>; /* PMU address offset */
		samsung,reset-sysreg = <&sysreg_csis_reset>;
		reset = <2>; /* reset bit */
		reg = <0x0 0x238F2300 0x500>, <0x0 0x238F2000 0x100>;
		reg-names = "clock", "bias";
		owner = <1>; /* 0: DSI,  1: CSI */
		#phy-cells = <0>;
	};

	mipi_dcphy_csis3_m0s4s4s4s4s4s4_s22: dcphy_m0s4s4s4s4s4s4_s22_csi3@238F2B00 {
		/* DPHY 6.5 Gbps 4lane */
		/* CPHY 6.5 Gbps 3lane */
		compatible = "samsung,mipi-phy-m0s4s4s4s4s4s4_s22";
		samsung,pmu-syscon = <&pmu_system_controller>;
		power-gating = <0x654>; /* PMU address offset */
		samsung,reset-sysreg = <&sysreg_csis_reset>;
		reset = <3>; /* reset bit */
		reg = <0x0 0x238F2B00 0x500>, <0x0 0x238F2000 0x100>;
		reg-names = "clock", "bias";
		owner = <1>; /* 0: DSI,  1: CSI */
		#phy-cells = <0>;
	};

	mipi_dcphy_csis4_m0s4s4s4s4s4s4_s22: dcphy_m0s4s4s4s4s4s4_s22_csi4@238F3300 {
		/* DPHY 6.5 Gbps 4lane */
		/* CPHY 6.5 Gbps 3lane */
		compatible = "samsung,mipi-phy-m0s4s4s4s4s4s4_s22";
		samsung,pmu-syscon = <&pmu_system_controller>;
		power-gating = <0x658>; /* PMU address offset */
		samsung,reset-sysreg = <&sysreg_csis_reset>;
		reset = <7>; /* reset bit */
		reg = <0x0 0x238F3300 0x500>, <0x0 0x238F3000 0x100>;
		reg-names = "clock", "bias";
		owner = <1>; /* 0: DSI,  1: CSI */
		#phy-cells = <0>;
	};

	mipi_dphy_csis5_m0s4s4s4s4s4s4_s22: dphy_m0s4s4s4s4s4s4_s22_csi5@238F3B00 {
		/* DPHY 6.5 Gbps 4lane */
		compatible = "samsung,mipi-phy-m0s4s4s4s4s4s4_s22";
		samsung,pmu-syscon = <&pmu_system_controller>;
		power-gating = <0x65C>; /* PMU address offset */
		samsung,reset-sysreg = <&sysreg_csis_reset>;
		reset = <4>; /* reset bit */
		reg = <0x0 0x238F3B00 0x500>, <0x0 0x238F3000 0x100>;
		reg-names = "clock", "bias";
		owner = <1>; /* 0: DSI,  1: CSI */
		#phy-cells = <0>;
	};

	/* 2 + 2 */
	mipi_dphy_csis6_m0s4s4s4s4s4s4_s22: dphy_m0s4s4s4s4s4s4_s22_csi5@238F3A00 {
		/* DPHY 6.5 Gbps 2lane */
		compatible = "samsung,mipi-phy-m0s4s4s4s4s4s4_s22";
		samsung,pmu-syscon = <&pmu_system_controller>;
		power-gating = <0x660>; /* PMU address offset */
		samsung,reset-sysreg = <&sysreg_csis_reset>;
		reset = <5>; /* reset bit */
		reg = <0x0 0x238F3A00 0x100>, <0x0 0x238F3E00 0x200>, <0x0 0x238F3000 0x100>;
		reg-names = "clock", "lane", "bias";
		owner = <1>; /* 0: DSI,  1: CSI */
		#phy-cells = <0>;
	};

	is_sensor0: is_sensor0@23880000 {
		/* CSIS0 */
		compatible = "samsung,exynos-is-sensor";
		reg = <0x0 0x23880000 0x1000>, /* MIPI-CSI0 */
			<0x0 0x238F0000 0x4000>, /* PHY: M0S4S4S4S4S4S4_S22 */
			<0x0 0x239D022C 0x10>, /* CSIS_FRO */
			<0x0 0x239D02A4 0x4>; /* EMB_LC MUX */
		reg-names = "csi", "phy", "fro", "emb_lc";
		interrupts = <0 INTREQ__CSIS0 IRQ_TYPE_LEVEL_HIGH>; /* MIPI-CSI0 */
		interrupt-names = "csi";
		phys = <&mipi_dcphy_csis0_m0s4s4s4s4s4s4_s22>;
		phy-names = "csis_dphy";
		phy_setfile = <&dcphy_setfile_cphy>;
		iommus = <&sysmmu_csis_s0>;
		samsung,iommu-group = <&iommu_group_is>;
	};

	is_sensor1: is_sensor1@23890000 {
		/* CSIS1 */
		compatible = "samsung,exynos-is-sensor";
		reg = <0x0 0x23890000 0x1000>, /* MIPI-CSI1 */
			<0x0 0x238F0000 0x4000>, /* PHY: M0S4S4S4S4S4S4_S22 */
			<0x0 0x239D022C 0x10>, /* CSIS_FRO */
			<0x0 0x239D02A8 0x4>; /* EMB_LC MUX */
		reg-names = "csi", "phy", "fro", "emb_lc";
		interrupts = <0 INTREQ__CSIS1 IRQ_TYPE_LEVEL_HIGH>; /* MIPI-CSI1 */
		interrupt-names = "csi";
		phys = <&mipi_dcphy_csis1_m0s4s4s4s4s4s4_s22>;
		phy-names = "csis_dphy";
		phy_setfile = <&dcphy_setfile_cphy>;
		iommus = <&sysmmu_csis_s0>;
		samsung,iommu-group = <&iommu_group_is>;
		samsung,tzmp;
	};

	is_sensor2: is_sensor2@238A0000 {
		/* CSIS2 */
		compatible = "samsung,exynos-is-sensor";
		reg = <0x0 0x238A0000 0x1000>, /* MIPI-CSI2 */
			<0x0 0x238F0000 0x4000>, /* PHY: M0S4S4S4S4S4S4_S22 */
			<0x0 0x239D022C 0x10>, /* CSIS_FRO */
			<0x0 0x239D02AC 0x4>; /* EMB_LC MUX */
		reg-names = "csi", "phy", "fro", "emb_lc";
		interrupts = <0 INTREQ__CSIS2 IRQ_TYPE_LEVEL_HIGH>; /* MIPI-CSI2 */
		interrupt-names = "csi";
		phys = <&mipi_dcphy_csis2_m0s4s4s4s4s4s4_s22>;
		phy-names = "csis_dphy";
		phy_setfile = <&dcphy_setfile_cphy>;
		iommus = <&sysmmu_csis_s0>;
		samsung,iommu-group = <&iommu_group_is>;
	};

	is_sensor3: is_sensor3@238B0000 {
		/* CSIS3 */
		compatible = "samsung,exynos-is-sensor";
		reg = <0x0 0x238B0000 0x1000>, /* MIPI-CSI3 */
			<0x0 0x238F0000 0x4000>, /* PHY: M0S4S4S4S4S4S4_S22 */
			<0x0 0x239D022C 0x10>, /* CSIS_FRO */
			<0x0 0x239D02B0 0x4>; /* EMB_LC MUX */
		reg-names = "csi", "phy", "fro", "emb_lc";
		interrupts = <0 INTREQ__CSIS3 IRQ_TYPE_LEVEL_HIGH>; /* MIPI-CSI3 */
		interrupt-names = "csi";
		phys = <&mipi_dcphy_csis3_m0s4s4s4s4s4s4_s22>;
		phy-names = "csis_dphy";
		phy_setfile = <&dcphy_setfile_cphy>;
		iommus = <&sysmmu_csis_s0>;
		samsung,iommu-group = <&iommu_group_is>;
	};

	is_sensor4: is_sensor4@238C0000 {
		/* CSIS4 */
		compatible = "samsung,exynos-is-sensor";
		reg = <0x0 0x238C0000 0x1000>, /* MIPI-CSI4 */
			<0x0 0x238F0000 0x4000>, /* PHY: M0S4S4S4S4S4S4_S22 */
			<0x0 0x239D022C 0x10>, /* CSIS_FRO */
			<0x0 0x239D02B4 0x4>; /* EMB_LC MUX */
		reg-names = "csi", "phy", "fro", "emb_lc";
		interrupts = <0 INTREQ__CSIS4 IRQ_TYPE_LEVEL_HIGH>; /* MIPI-CSI4 */
		interrupt-names = "csi";
		phys = <&mipi_dcphy_csis4_m0s4s4s4s4s4s4_s22>;
		phy-names = "csis_dphy";
		phy_setfile = <&dcphy_setfile_cphy>;
		iommus = <&sysmmu_csis_s0>;
		samsung,iommu-group = <&iommu_group_is>;
	};

	is_sensor5: is_sensor5@238D0000 {
		/* CSIS5 */
		compatible = "samsung,exynos-is-sensor";
		reg = <0x0 0x238D0000 0x1000>, /* MIPI-CSI5 */
			<0x0 0x238F0000 0x4000>, /* PHY: M0S4S4S4S4S4S4_S22 */
			<0x0 0x239D022C 0x10>, /* CSIS_FRO */
			<0x0 0x239D02B8 0x4>; /* EMB_LC MUX */
		reg-names = "csi", "phy", "fro", "emb_lc";
		interrupts = <0 INTREQ__CSIS5 IRQ_TYPE_LEVEL_HIGH>; /* MIPI-CSI5 */
		interrupt-names = "csi";
		phys = <&mipi_dphy_csis5_m0s4s4s4s4s4s4_s22>;
		phy-names = "csis_dphy";
		phy_setfile = <&dcphy_setfile_cphy>;
		iommus = <&sysmmu_csis_s0>;
		samsung,iommu-group = <&iommu_group_is>;
	};

	sensor_paf_pdp_0: sensor-paf-pdp@23980000 {
		compatible = "samsung,sensor-paf-pdp";
		reg = <0x0 0x23980000 0xb000>, /* PDP CORE0 */
			<0x0 0x23980000 0xb000>; /* PDP CORE0: For common regiser */
		reg-names = "core", "common";
		interrupts = <0 INTREQ__PDP0 IRQ_TYPE_LEVEL_HIGH>,
			<0 INTREQ__PDP1 IRQ_TYPE_LEVEL_HIGH>;
	};

	sensor_paf_pdp_1: sensor-paf-pdp@23990000 {
		compatible = "samsung,sensor-paf-pdp";
		reg = <0x0 0x23990000 0xb000>, /* PDP CORE1 */
			<0x0 0x23990000 0xb000>; /* PDP CORE0: For common regiser */
		reg-names = "core", "common";
		interrupts = <0 INTREQ__PDP2 IRQ_TYPE_LEVEL_HIGH>,
			<0 INTREQ__PDP3 IRQ_TYPE_LEVEL_HIGH>;
	};

	sensor_paf_pdp_2: sensor-paf-pdp@239A0000 {
		compatible = "samsung,sensor-paf-pdp";
		reg = <0x0 0x239A0000 0xb000>, /* PDP CORE2 */
			<0x0 0x239A0000 0xb000>; /* PDP CORE0: For common regiser */
		reg-names = "core", "common";
		interrupts = <0 INTREQ__PDP4 IRQ_TYPE_LEVEL_HIGH>,
			<0 INTREQ__PDP5 IRQ_TYPE_LEVEL_HIGH>;
	};

	sensor_paf_pdp_3: sensor-paf-pdp@239B0000 {
		compatible = "samsung,sensor-paf-pdp";
		reg = <0x0 0x239B0000 0xb000>, /* PDP CORE3 */
			<0x0 0x239B0000 0xb000>; /* PDP CORE0: For common regiser */
		reg-names = "core", "common";
		interrupts = <0 INTREQ__PDP6 IRQ_TYPE_LEVEL_HIGH>,
			<0 INTREQ__PDP7 IRQ_TYPE_LEVEL_HIGH>;
	};

	aliases {
		pdp0 = &sensor_paf_pdp_0;
		pdp1 = &sensor_paf_pdp_1;
		pdp2 = &sensor_paf_pdp_2;
		pdp3 = &sensor_paf_pdp_3;
	};

	/*
	 * default setfiles for DPHY & CPHY
	 * <addr, bit_start, bit_width, val, index, max_lane>
	 *
	 * CSD : lane0, lane1, lane2
	 * SD  : lane3
	 */
	dcphy_setfile_dphy: dcphy-setfile-dphy@0 {
		comm {
			/* bias */
			0  = <0x0000 0 32 0x00100004 IDX_BIA_VAL 0>; /* BIAS_CON0 */
			1  = <0x0004 0 32 0x00003023 IDX_BIA_VAL 0>; /* BIAS_CON1 */
			2  = <0x0008 0 32 0x00000100 IDX_BIA_VAL 0>; /* BIAS_CON2 */

			/* Clock lane */
			3  = <0x0000 0 32 0x3C000000 IDX_FIX_VAL 0>; /* SC_GNR_CON0 */
			4  = <0x0008 0 32 0x24F20401 IDX_FIX_VAL 0>; /* SC_ANA_CON0 */
			5  = <0x000C 0 32 0x82090004 IDX_FIX_VAL 0>; /* SC_ANA_CON1 */
			6  = <0x0010 0 32 0x00004000 IDX_FIX_VAL 0>; /* SC_ANA_CON2 */
			7  = <0x0014 0 32 0x00000001 IDX_FIX_VAL 0>; /* SC_ANA_CON3 */
			8  = <0x0030 0 32 0x00000712 IDX_FIX_VAL 0>; /* SC_TIME_CON0 */
			9  = <0x0070 0 32 0x00000030 IDX_FIX_VAL 0>; /* SC_TEST_CON0 */

			/* Clock enable should be set at last */
			10 = <0x0000 0 1 0x00000001 IDX_FIX_VAL 0>; /* SC_GNR_CON0 */
		};

		lane {
			0  = <0x0000 0 32 0x3C000000 IDX_FIX_VAL 4>; /* SD_GNR_CON0 */
			1  = <0x0008 0 32 0x24F20001 IDX_FIX_VAL 4>; /* SD_ANA_CON0 */
			2  = <0x0008 0 32 0x24F21001 IDX_FIX_VAL 3>; /* CSD_ANA_CON0 */
			3  = <0x000C 0 32 0x82090004 IDX_FIX_VAL 4>; /* CSD/SD_ANA_CON1 */
			4  = <0x000C 8  2 0x00000000 IDX_SKW_DLY 4>; /* CSD/SD_ANA_CON1 */
			5  = <0x0010 0 32 0x00002000 IDX_FIX_VAL 4>; /* SD_ANA_CON2 */
			6  = <0x0010 0 32 0x09004000 IDX_FIX_VAL 3>; /* CSD_ANA_CON2 */
			7  = <0x0014 0 32 0x00400000 IDX_FIX_VAL 3>; /* CSD_ANA_CON3 */
			8  = <0x0030 0 32 0x00030000 IDX_FIX_VAL 4>; /* SD_TIME_CON0 */
			9  = <0x0030 0 32 0x00018000 IDX_FIX_VAL 3>; /* CSD_TIME_CON0 */
			10 = <0x0030 0  8 0x00000000 IDX_STL_VAL 4>; /* CSD/SD_TIME_CON0 */
			11 = <0x0030 8  1 0x00000000 IDX_STL_CLK 4>; /* CSD/SD_TIME_CON0 */
			12 = <0x0040 0  1 0x00000001 IDX_SKW_CAL 4>; /* CSD/SD_DESKEW_CON0 */
			13 = <0x0048 0 32 0x0000081A IDX_FIX_VAL 4>; /* CSD/SD_DESKEW_CON2 */
			14 = <0x0070 0 32 0x00000030 IDX_FIX_VAL 4>; /* CSD/SD_TEST_CON0 */

			/* Data enable should be set at last */
			15 = <0x0000 0 1 0x00000001 IDX_FIX_VAL 4>; /* SD_GNR_CON0 */
		};
	};

	dcphy_setfile_cphy: dcphy-setfile-cphy@0 {
		comm {
			/* bias */
			0  = <0x0000 0 32 0x00100004 IDX_BIA_VAL 0>; /* BIAS_CON0 */
			1  = <0x0004 0 32 0x00003023 IDX_BIA_VAL 0>; /* BIAS_CON1 */
			2  = <0x0008 0 32 0x00000140 IDX_BIA_VAL 0>; /* BIAS_CON2 */

			/* Clock lane */
			3  = <0x000C 0 32 0x82090004 IDX_FIX_VAL 0>; /* SC_ANA_CON1 */
			4  = <0x0010 0 32 0x00004000 IDX_FIX_VAL 0>; /* SC_ANA_CON2 */
		};

		lane {
			0  = <0x0000 0 32 0x3C000000 IDX_FIX_VAL 3>; /* CSD_GNR_CON0 */
			1  = <0x0008 0 32 0xECF111FB IDX_FIX_VAL 3>; /* CSD_ANA_CON0 */
			2  = <0x000C 0 32 0x82090004 IDX_FIX_VAL 4>; /* CSD/SD_ANA_CON1 */
			3  = <0x0010 0 32 0x00002000 IDX_FIX_VAL 4>; /* SD_ANA_CON2 */
			4  = <0x0010 0 32 0x09004000 IDX_FIX_VAL 3>; /* CSD_ANA_CON2 */
			5  = <0x0014 0 32 0x00400808 IDX_FIX_VAL 3>; /* CSD_ANA_CON3 */
			6  = <0x0030 0 32 0x00280000 IDX_FIX_VAL 3>; /* CSD_TIME_CON0 */
			7  = <0x0030 8  1 0x00000000 IDX_STL_CLK 3>; /* CSD_TIME_CON0 */
			8  = <0x0034 0 32 0x00000040 IDX_FIX_VAL 3>; /* CSD_TIME_CON1 */
			9  = <0x0050 0 32 0x15010000 IDX_FIX_VAL 3>; /* CSD_CRC_CON0 */
			10 = <0x0054 0 32 0x0000000F IDX_FIX_VAL 3>; /* CSD_CRC_CON1 */
			11 = <0x0070 0 32 0x00000030 IDX_FIX_VAL 3>; /* CSD_TEST_CON0 */

			/* Data enable should be set at last */
			12 = <0x0000 0 1 0x00000001 IDX_FIX_VAL 3>; /* CSD_GNR_CON0 */
		};
	};
};
